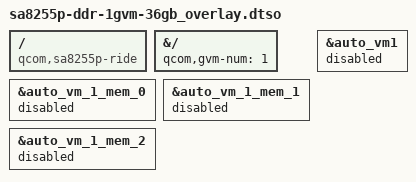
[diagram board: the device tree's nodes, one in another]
// SPDX-License-Identifier: BSD-3-Clause
/*
 * Copyright (c) Qualcomm Technologies, Inc. and/or its subsidiaries.
 */
/dts-v1/;
/plugin/;

/ {
	compatible = "qcom,sa8255p-ride";
};

&{/} {
	qcom,gvm-num = <1>;
};

&auto_vm_1_mem_0 {
	status = "disabled";
};

&auto_vm_1_mem_1 {
	status = "disabled";
};

&auto_vm_1_mem_2 {
	status = "disabled";
};

&auto_vm1 {
	status = "disabled";
};
